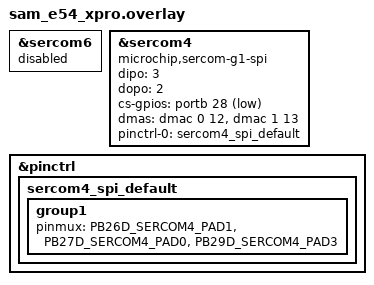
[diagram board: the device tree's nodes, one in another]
/*
 * Copyright (c) 2026 Microchip Technology Inc.
 *
 * SPDX-License-Identifier: Apache-2.0
 */

&sercom6 {
	status = "disabled";
};

#define SPI_LOOPBACK_FAST_HZ 24000000

spi_loopback: &sercom4 {
	compatible = "microchip,sercom-g1-spi";
	/* Internally connect MOSI to MISO for loop-back operation */
	dipo = <3>;
	dopo = <2>;
	/* Assign a CS pin */
	cs-gpios = <&portb 28 GPIO_ACTIVE_LOW>;
	/* Configure DMA */
	dmas = <&dmac 0 12>, <&dmac 1 13>;
	dma-names = "rx", "tx";

	#address-cells = <1>;
	#size-cells = <0>;
	pinctrl-0 = <&sercom4_spi_default>;
	pinctrl-names = "default";
	status = "okay";
};

&pinctrl {
	sercom4_spi_default: sercom4_spi_default {
		group1 {
			pinmux = <PB26D_SERCOM4_PAD1>,
				 <PB27D_SERCOM4_PAD0>,
				 <PB29D_SERCOM4_PAD3>;
		};
	};
};

#include "../spi-loopback.dtsi"
